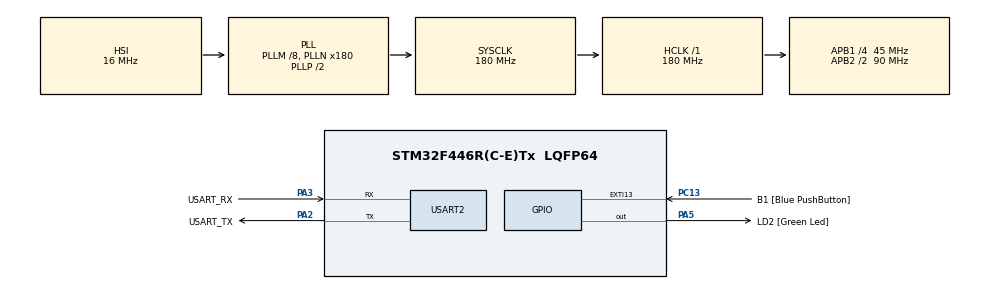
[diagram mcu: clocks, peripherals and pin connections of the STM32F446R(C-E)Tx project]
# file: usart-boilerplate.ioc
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Dma.Request0=USART2_RX
Dma.Request1=USART2_TX
Dma.USART2_RX.0.Direction=DMA_PERIPH_TO_MEMORY
Dma.USART2_RX.0.FIFOMode=DMA_FIFOMODE_DISABLE
Dma.USART2_RX.0.Instance=DMA1_Stream5
Dma.USART2_RX.0.MemDataAlignment=DMA_MDATAALIGN_BYTE
Dma.USART2_RX.0.MemInc=DMA_MINC_ENABLE
Dma.USART2_RX.0.Mode=DMA_NORMAL
Dma.USART2_RX.0.PeriphDataAlignment=DMA_PDATAALIGN_BYTE
Dma.USART2_RX.0.PeriphInc=DMA_PINC_DISABLE
Dma.USART2_RX.0.Priority=DMA_PRIORITY_LOW
Dma.USART2_TX.1.Direction=DMA_MEMORY_TO_PERIPH
Dma.USART2_TX.1.FIFOMode=DMA_FIFOMODE_DISABLE
Dma.USART2_TX.1.Instance=DMA1_Stream6
Dma.USART2_TX.1.MemDataAlignment=DMA_MDATAALIGN_BYTE
Dma.USART2_TX.1.MemInc=DMA_MINC_ENABLE
Dma.USART2_TX.1.Mode=DMA_NORMAL
Dma.USART2_TX.1.PeriphDataAlignment=DMA_PDATAALIGN_BYTE
Dma.USART2_TX.1.PeriphInc=DMA_PINC_DISABLE
Dma.USART2_TX.1.Priority=DMA_PRIORITY_LOW
FREERTOS.Tasks01=defaultTask,0,128,StartDefaultTask,Default,NULL,Dynamic,NULL,NULL
FREERTOS.configUSE_NEWLIB_REENTRANT=1
Mcu.Family=STM32F4
Mcu.Name=STM32F446R(C-E)Tx
Mcu.Package=LQFP64
NVIC.DMA1_Stream5_IRQn=true\:5\:0\:false\:false\:true\:true\:false\:true
NVIC.DMA1_Stream6_IRQn=true\:5\:0\:false\:false\:true\:true\:false\:true
NVIC.PriorityGroup=NVIC_PRIORITYGROUP_4
NVIC.USART2_IRQn=true\:5\:0\:false\:false\:true\:true\:true\:true
PA13.GPIO_Label=TMS
PA13.Mode=Trace_Asynchronous_SW
PA13.Signal=SYS_JTMS-SWDIO
PA14.GPIO_Label=TCK
PA14.Mode=Trace_Asynchronous_SW
PA14.Signal=SYS_JTCK-SWCLK
PA2.GPIO_Label=USART_TX
PA2.Mode=Asynchronous
PA2.Signal=USART2_TX
PA3.GPIO_Label=USART_RX
PA3.Mode=Asynchronous
PA3.Signal=USART2_RX
PA5.GPIO_Label=LD2 [Green Led]
PA5.Signal=GPIO_Output
PB3.GPIO_Label=SWO
PB3.Mode=Trace_Asynchronous_SW
PB3.Signal=SYS_JTDO-SWO
PC13.GPIO_Label=B1 [Blue PushButton]
PC13.GPIO_ModeDefaultEXTI=GPIO_MODE_IT_FALLING
PC13.Signal=GPXTI13
PC14-OSC32_IN.Signal=RCC_OSC32_IN
PC15-OSC32_OUT.Signal=RCC_OSC32_OUT
PH0-OSC_IN.Signal=RCC_OSC_IN
PH1-OSC_OUT.Signal=RCC_OSC_OUT
ProjectManager.HeapSize=0x200
ProjectManager.StackSize=0x400
ProjectManager.TargetToolchain=STM32CubeIDE
RCC.48MHZClocksFreq_Value=84000000
RCC.AHBFreq_Value=180000000
RCC.APB1CLKDivider=RCC_HCLK_DIV4
RCC.APB1Freq_Value=45000000
RCC.APB1TimFreq_Value=90000000
RCC.APB2CLKDivider=RCC_HCLK_DIV2
RCC.APB2Freq_Value=90000000
RCC.APB2TimFreq_Value=180000000
RCC.CortexFreq_Value=180000000
RCC.FLatency-AdvancedSettings=FLASH_LATENCY_5
RCC.HCLKFreq_Value=180000000
RCC.HSE_VALUE=8000000
RCC.HSI_VALUE=16000000
RCC.PLLM=8
RCC.PLLN=180
RCC.SYSCLKFreq_VALUE=180000000
RCC.SYSCLKSource=RCC_SYSCLKSOURCE_PLLCLK
RCC.USBFreq_Value=180000000
RCC.VCOOutputFreq_Value=360000000
USART2.OverSampling=UART_OVERSAMPLING_16
USART2.VirtualMode=VM_ASYNC
VP_FREERTOS_VS_CMSIS_V1.Mode=CMSIS_V1
board=NUCLEO-F446RE

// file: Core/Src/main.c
/* USER CODE BEGIN Header */
/**
  ******************************************************************************
  * @file           : main.c
  * @brief          : Main program body
  ******************************************************************************
  * @attention
  *
  * <h2><center>&copy; Copyright (c) 2021 STMicroelectronics.
  * All rights reserved.</center></h2>
  *
  * This software component is licensed by ST under BSD 3-Clause license,
  * the "License"; You may not use this file except in compliance with the
  * License. You may obtain a copy of the License at:
  *                        opensource.org/licenses/BSD-3-Clause
  *
  ******************************************************************************
  */
/* USER CODE END Header */
#include "main.h"
#include "cmsis_os.h"
#include "dma.h"
#include "usart.h"
#include "gpio.h"

void SystemClock_Config(void);
void MX_FREERTOS_Init(void);

int main(void)
{

  /* MCU Configuration--------------------------------------------------------*/

  /* Reset of all peripherals, Initializes the Flash interface and the Systick. */
  HAL_Init();

  /* Configure the system clock */
  SystemClock_Config();

  /* USER CODE BEGIN SysInit */
  MX_DMA_Init();
  /* USER CODE END SysInit */

  /* Initialize all configured peripherals */
  MX_GPIO_Init();
  MX_USART2_UART_Init();
  MX_DMA_Init();

  /* Call init function for freertos objects (in freertos.c) */
  MX_FREERTOS_Init();
  /* Start scheduler */
  osKernelStart();

  /* We should never get here as control is now taken by the scheduler */
  /* Infinite loop */
  while (1)
  {

  }
}

void SystemClock_Config(void)
{
  RCC_OscInitTypeDef RCC_OscInitStruct = {0};
  RCC_ClkInitTypeDef RCC_ClkInitStruct = {0};

  /** Configure the main internal regulator output voltage
  */
  __HAL_RCC_PWR_CLK_ENABLE();
  __HAL_PWR_VOLTAGESCALING_CONFIG(PWR_REGULATOR_VOLTAGE_SCALE1);
  /** Initializes the RCC Oscillators according to the specified parameters
  * in the RCC_OscInitTypeDef structure.
  */
  RCC_OscInitStruct.OscillatorType = RCC_OSCILLATORTYPE_HSI;
  RCC_OscInitStruct.HSIState = RCC_HSI_ON;
  RCC_OscInitStruct.HSICalibrationValue = RCC_HSICALIBRATION_DEFAULT;
  RCC_OscInitStruct.PLL.PLLState = RCC_PLL_ON;
  RCC_OscInitStruct.PLL.PLLSource = RCC_PLLSOURCE_HSI;
  RCC_OscInitStruct.PLL.PLLM = 8;
  RCC_OscInitStruct.PLL.PLLN = 180;
  RCC_OscInitStruct.PLL.PLLP = RCC_PLLP_DIV2;
  RCC_OscInitStruct.PLL.PLLQ = 2;
  RCC_OscInitStruct.PLL.PLLR = 2;
  if (HAL_RCC_OscConfig(&RCC_OscInitStruct) != HAL_OK)
  {
    Error_Handler();
  }
  /** Activate the Over-Drive mode
  */
  if (HAL_PWREx_EnableOverDrive() != HAL_OK)
  {
    Error_Handler();
  }
  /** Initializes the CPU, AHB and APB buses clocks
  */
  RCC_ClkInitStruct.ClockType = RCC_CLOCKTYPE_HCLK|RCC_CLOCKTYPE_SYSCLK
                              |RCC_CLOCKTYPE_PCLK1|RCC_CLOCKTYPE_PCLK2;
  RCC_ClkInitStruct.SYSCLKSource = RCC_SYSCLKSOURCE_PLLCLK;
  RCC_ClkInitStruct.AHBCLKDivider = RCC_SYSCLK_DIV1;
  RCC_ClkInitStruct.APB1CLKDivider = RCC_HCLK_DIV4;
  RCC_ClkInitStruct.APB2CLKDivider = RCC_HCLK_DIV2;

  if (HAL_RCC_ClockConfig(&RCC_ClkInitStruct, FLASH_LATENCY_5) != HAL_OK)
  {
    Error_Handler();
  }
}

void Error_Handler(void)
{
  __disable_irq();
  while (1)
  {
  }
}

/************************ (C) COPYRIGHT STMicroelectronics *****END OF FILE****/

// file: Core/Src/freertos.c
/* USER CODE BEGIN Header */
/**
  ******************************************************************************
  * File Name          : freertos.c
  * Description        : Code for freertos applications
  ******************************************************************************
  * @attention
  *
  * <h2><center>&copy; Copyright (c) 2021 STMicroelectronics.
  * All rights reserved.</center></h2>
  *
  * This software component is licensed by ST under Ultimate Liberty license
  * SLA0044, the "License"; You may not use this file except in compliance with
  * the License. You may obtain a copy of the License at:
  *                             www.st.com/SLA0044
  *
  ******************************************************************************
  */
/* USER CODE END Header */

#include "FreeRTOS.h"
#include "task.h"
#include "main.h"
#include "cmsis_os.h"

/* USER CODE BEGIN Includes */
#include "usart.h"
/* USER CODE END Includes */

osThreadId defaultTaskHandle;

void StartDefaultTask(void const * argument);

void MX_FREERTOS_Init(void); /* (MISRA C 2004 rule 8.1) */

/* GetIdleTaskMemory prototype (linked to static allocation support) */
void vApplicationGetIdleTaskMemory( StaticTask_t **ppxIdleTaskTCBBuffer, StackType_t **ppxIdleTaskStackBuffer, uint32_t *pulIdleTaskStackSize );

/* USER CODE BEGIN GET_IDLE_TASK_MEMORY */
static StaticTask_t xIdleTaskTCBBuffer;
static StackType_t xIdleStack[configMINIMAL_STACK_SIZE];

void vApplicationGetIdleTaskMemory( StaticTask_t **ppxIdleTaskTCBBuffer, StackType_t **ppxIdleTaskStackBuffer, uint32_t *pulIdleTaskStackSize )
{
  *ppxIdleTaskTCBBuffer = &xIdleTaskTCBBuffer;
  *ppxIdleTaskStackBuffer = &xIdleStack[0];
  *pulIdleTaskStackSize = configMINIMAL_STACK_SIZE;
  /* place for user code */
}
/* USER CODE END GET_IDLE_TASK_MEMORY */

void MX_FREERTOS_Init(void) {

  /* Create the thread(s) */
  /* definition and creation of defaultTask */
  osThreadDef(defaultTask, StartDefaultTask, osPriorityNormal, 0, 128);
  defaultTaskHandle = osThreadCreate(osThread(defaultTask), NULL);

}

void StartDefaultTask(void const * argument)
{
  /* USER CODE BEGIN StartDefaultTask */
	while (1){
		uint8_t temp_buffer[64];
		size_t read_bytes;
		read_bytes =get_rx_data(temp_buffer, sizeof(temp_buffer), 100);
		put_tx_data_with_wait(temp_buffer,read_bytes);
	}
  /* USER CODE END StartDefaultTask */
}

/************************ (C) COPYRIGHT STMicroelectronics *****END OF FILE****/
